VERSION "0.2-draft"

BU_: EFI ABS CLUSTER M7

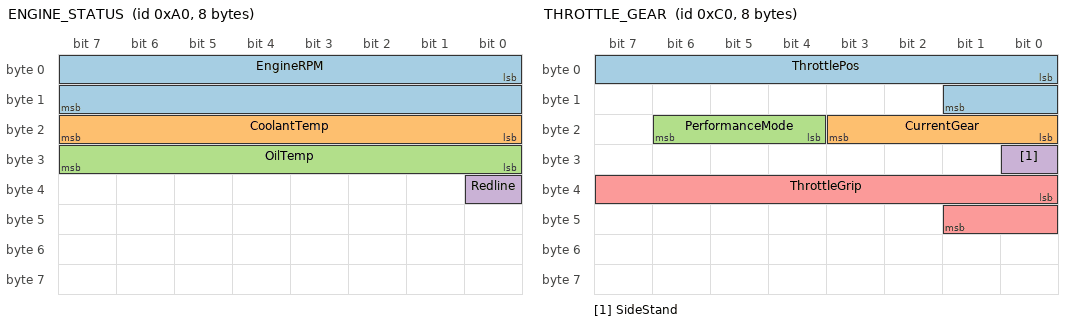
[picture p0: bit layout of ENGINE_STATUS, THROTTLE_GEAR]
BO_ 160 ENGINE_STATUS : 8 EFI
 SG_ EngineRPM : 0|16@1+ (1,0) [0|65535] "rpm" CLUSTER,ABS,M7
 SG_ CoolantTemp : 16|8@1+ (1,-40) [-40|215] "celsius" CLUSTER,M7
 SG_ OilTemp : 24|8@1+ (1,-40) [-40|215] "celsius" CLUSTER,M7
 SG_ Redline : 32|1@1+ (1,0) [0|1] "" CLUSTER,M7

BO_ 192 THROTTLE_GEAR : 8 EFI
 SG_ ThrottlePos : 0|10@1+ (0.1,0) [0|102.3] "percent" CLUSTER,ABS,M7
 SG_ CurrentGear : 16|4@1+ (1,0) [0|15] "" CLUSTER,ABS,M7
 SG_ PerformanceMode : 20|3@1+ (1,0) [0|7] "" CLUSTER,ABS,M7
 SG_ SideStand : 24|1@1+ (1,0) [0|1] "" CLUSTER,M7
 SG_ ThrottleGrip : 32|10@1+ (0.1,0) [0|102.3] "percent" CLUSTER,M7

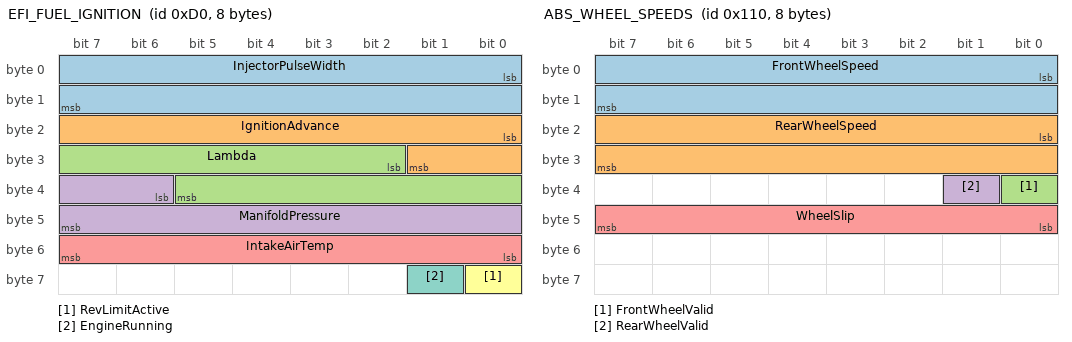
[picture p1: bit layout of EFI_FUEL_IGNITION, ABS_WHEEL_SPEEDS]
BO_ 208 EFI_FUEL_IGNITION : 8 EFI
 SG_ InjectorPulseWidth : 0|16@1+ (0.001,0) [0|65.535] "ms" M7
 SG_ IgnitionAdvance : 16|10@1+ (0.1,-20) [-20|82.3] "deg" M7
 SG_ Lambda : 26|12@1+ (0.001,0.5) [0.5|4.595] "" M7
 SG_ ManifoldPressure : 38|10@1+ (0.25,0) [0|255.75] "kPa" M7
 SG_ IntakeAirTemp : 48|8@1+ (1,-40) [-40|215] "celsius" M7
 SG_ RevLimitActive : 56|1@1+ (1,0) [0|1] "" CLUSTER,M7
 SG_ EngineRunning : 57|1@1+ (1,0) [0|1] "" CLUSTER,M7

BO_ 224 RIDE_MODE_REQUEST : 2 CLUSTER
 SG_ RequestedMode : 0|3@1+ (1,0) [0|7] "" EFI,ABS,M7
 SG_ TripResetRequest : 4|2@1+ (1,0) [0|3] "" M7

BO_ 272 ABS_WHEEL_SPEEDS : 8 ABS
 SG_ FrontWheelSpeed : 0|16@1+ (0.1,0) [0|6553.5] "km/h" EFI,CLUSTER,M7
 SG_ RearWheelSpeed : 16|16@1+ (0.1,0) [0|6553.5] "km/h" EFI,CLUSTER,M7
 SG_ FrontWheelValid : 32|1@1+ (1,0) [0|1] "" EFI,CLUSTER,M7
 SG_ RearWheelValid : 33|1@1+ (1,0) [0|1] "" EFI,CLUSTER,M7
 SG_ WheelSlip : 40|8@1+ (0.5,-64) [-64|63.5] "percent" EFI,CLUSTER,M7

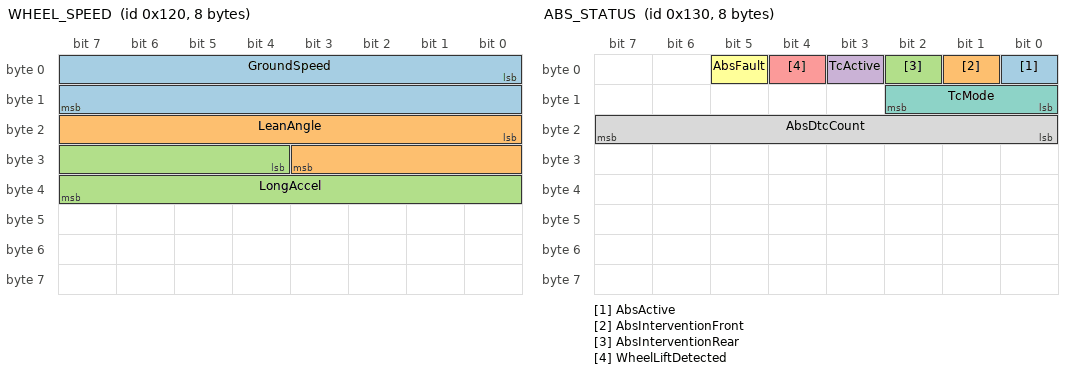
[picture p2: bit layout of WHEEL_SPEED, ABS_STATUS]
BO_ 288 WHEEL_SPEED : 8 ABS
 SG_ GroundSpeed : 0|16@1+ (0.1,0) [0|6553.5] "km/h" CLUSTER,M7
 SG_ LeanAngle : 16|12@1+ (0.1,-90) [-90|319.5] "deg" CLUSTER,M7
 SG_ LongAccel : 28|12@1+ (0.01,-20) [-20|20.95] "g" CLUSTER,M7

BO_ 304 ABS_STATUS : 8 ABS
 SG_ AbsActive : 0|1@1+ (1,0) [0|1] "" CLUSTER,M7
 SG_ AbsInterventionFront : 1|1@1+ (1,0) [0|1] "" CLUSTER,M7
 SG_ AbsInterventionRear : 2|1@1+ (1,0) [0|1] "" CLUSTER,M7
 SG_ TcActive : 3|1@1+ (1,0) [0|1] "" CLUSTER,M7
 SG_ WheelLiftDetected : 4|1@1+ (1,0) [0|1] "" CLUSTER,M7
 SG_ AbsFault : 5|1@1+ (1,0) [0|1] "" CLUSTER,M7
 SG_ TcMode : 8|3@1+ (1,0) [0|7] "" CLUSTER,M7
 SG_ AbsDtcCount : 16|8@1+ (1,0) [0|255] "" CLUSTER,M7

BO_ 320 ABS_BRAKE_PRESSURE : 8 ABS
 SG_ FrontBrakePressure : 0|12@1+ (0.05,0) [0|204.75] "bar" CLUSTER,M7
 SG_ RearBrakePressure : 16|12@1+ (0.05,0) [0|204.75] "bar" CLUSTER,M7

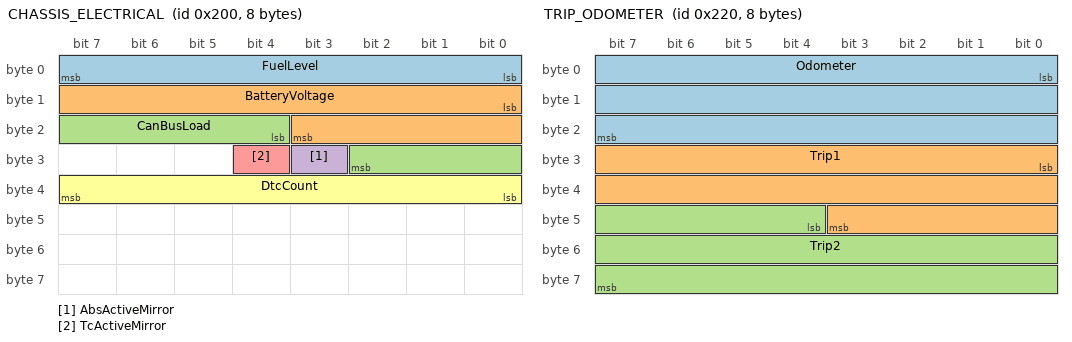
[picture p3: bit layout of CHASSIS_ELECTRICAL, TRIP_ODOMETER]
BO_ 512 CHASSIS_ELECTRICAL : 8 M7
 SG_ FuelLevel : 0|8@1+ (0.5,0) [0|127.5] "percent" CLUSTER
 SG_ BatteryVoltage : 8|12@1+ (0.01,0) [0|40.95] "V" CLUSTER
 SG_ CanBusLoad : 20|7@1+ (1,0) [0|127] "percent" CLUSTER
 SG_ AbsActiveMirror : 27|1@1+ (1,0) [0|1] "" CLUSTER
 SG_ TcActiveMirror : 28|1@1+ (1,0) [0|1] "" CLUSTER
 SG_ DtcCount : 32|8@1+ (1,0) [0|255] "" CLUSTER

BO_ 544 TRIP_ODOMETER : 8 CLUSTER
 SG_ Odometer : 0|24@1+ (0.1,0) [0|1677721.5] "km" M7
 SG_ Trip1 : 24|20@1+ (0.1,0) [0|104857.5] "km" M7
 SG_ Trip2 : 44|20@1+ (0.1,0) [0|104857.5] "km" M7

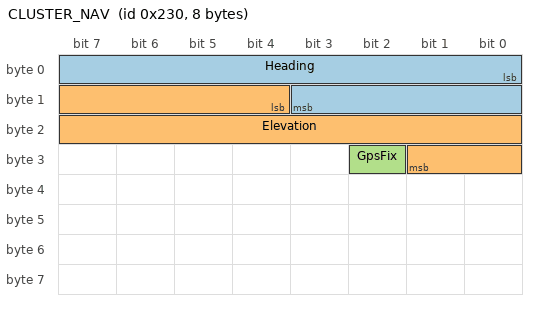
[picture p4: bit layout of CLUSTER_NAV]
BO_ 560 CLUSTER_NAV : 8 CLUSTER
 SG_ Heading : 0|12@1+ (0.1,0) [0|409.5] "deg" M7
 SG_ Elevation : 12|14@1+ (1,-1000) [-1000|15383] "m" M7
 SG_ GpsFix : 26|1@1+ (1,0) [0|1] "" M7

CM_ "Sigma Racer full-vehicle bus (XSR900 GP platform). Supersedes m7-draft.dbc: the five draft messages keep their IDs and layouts, re-homed to their true source nodes. M7 is the iMX8MP Cortex-M7 gateway (sidearm) and receives everything it does not send for logging and rpmsg bridging.";
CM_ BU_ EFI "Engine control unit (sigma-racer-efi, MRE board, Yamaha CP3)";
CM_ BU_ ABS "Brake/traction module: wheel speeds, IMU-fused motion, intervention state";
CM_ BU_ CLUSTER "Instrument cluster on the iMX8MP A53 cores (sigma-racer-cluster)";
CM_ BU_ M7 "Safety-core gateway (sigma-racer-sidearm); aggregates and bridges to rpmsg";
CM_ BO_ 208 "ECU internals for datalogging and tuning; flag bits mirrored to the cluster";
CM_ BO_ 224 "Rider input from cluster UI: mode selection and trip reset (event-driven)";
CM_ BO_ 272 "Per-wheel speeds from the ABS sensor rings; WheelSlip is rear-vs-front";
CM_ BO_ 288 "IMU-fused motion; name kept from m7-draft for decoder compatibility";
CM_ BO_ 320 "Front/rear master-cylinder line pressure; split from ABS_STATUS to stay within the 8-signal no_std codec capacity";
CM_ BO_ 512 "M7 aggregate retained for draft consumers; Mirror signals duplicate ABS_STATUS and will be dropped once all consumers read the source messages";
CM_ SG_ 192 ThrottleGrip "Rider demand from the RbW grip sensor pair; ThrottlePos is the plate";
CM_ SG_ 272 WheelSlip "Rear vs front wheel slip; positive means rear overspeed (spin)";

BA_DEF_ BO_ "GenMsgCycleTime" INT 0 65535;
BA_DEF_ BO_ "GenMsgSendType" ENUM "Cyclic","Event";
BA_DEF_DEF_ "GenMsgCycleTime" 100;
BA_DEF_DEF_ "GenMsgSendType" "Cyclic";

BA_ "GenMsgCycleTime" BO_ 160 20;
BA_ "GenMsgCycleTime" BO_ 192 20;
BA_ "GenMsgCycleTime" BO_ 208 50;
BA_ "GenMsgCycleTime" BO_ 224 0;
BA_ "GenMsgSendType" BO_ 224 "Event";
BA_ "GenMsgCycleTime" BO_ 272 20;
BA_ "GenMsgCycleTime" BO_ 288 50;
BA_ "GenMsgCycleTime" BO_ 304 50;
BA_ "GenMsgCycleTime" BO_ 320 20;
BA_ "GenMsgCycleTime" BO_ 544 1000;
BA_ "GenMsgCycleTime" BO_ 560 200;

VAL_ 192 PerformanceMode 0 "RAIN" 1 "STD" 2 "SPORT" 3 "TRACK" ;
VAL_ 224 RequestedMode 0 "RAIN" 1 "STD" 2 "SPORT" 3 "TRACK" ;
VAL_ 224 TripResetRequest 0 "NONE" 1 "TRIP1" 2 "TRIP2" 3 "BOTH" ;
VAL_ 304 TcMode 0 "OFF" 1 "LEVEL_1" 2 "LEVEL_2" 3 "MANUAL" ;
